AUTOSAR XML (schema 4.0)
standard types defined: float32, float64, sint16, sint32, sint8, uint16, uint32, uint8, void, boolean
package /ImplDataTypes
  7 x impl type, all with category=TYPE_REFERENCE, implementation-data-type=uint8, type-emitter=RTE:
    HeightImpType
    InclineImpType
    MultiStateBtnType
    SensorPositionType
    SensorWeightType
    SlideImpType
    StepMotorStepImpType
package /MappingSets
  data type mapping set MappingSet
package /PortInterfaces/ClientServer
  7 x client server interface:
    CsIf_HeightMotor
      operation Move
        arg Step: type=StepMotorStepImpType, direction=IN
    CsIf_HeightSensor
      operation GetPosition
        arg Arg_: type=SensorPositionType, direction=OUT
    CsIf_InclineMotor
      operation Move
        arg Step: type=StepMotorStepImpType, direction=IN
    CsIf_InclineSensor
      operation GetPosition
        arg Arg_: type=SensorPositionType, direction=OUT
    CsIf_SlideMotor
      operation Move
        arg Step: type=StepMotorStepImpType, direction=IN
    CsIf_SlideSensor
      operation GetPosition
        arg Arg_: type=SensorPositionType, direction=OUT
    CsIf_WeightSensor
      operation GetWeight
        arg Arg_: type=SensorWeightType, direction=OUT
package /PortInterfaces/SenderReceiver
  sender receiver interface SrIf_SeatCtrlBtns
    data HeightBtnState: type=MultiStateBtnType
    data InclineBtnState: type=MultiStateBtnType
    data SlideBtnState: type=MultiStateBtnType
  sender receiver interface SrIf_SeatCtrlData
    data Height: type=HeightImpType
    data Incline: type=InclineImpType
    data Slide: type=SlideImpType
package /SoftwareComponents
  application sw component type ECU
    provide port ppSeatCtrlData: provided-interface=SrIf_SeatCtrlData
    behavior Ibhv_ECU: data-type-mapping=MappingSet, handle-termination-and-restart=NO-SUPPORT
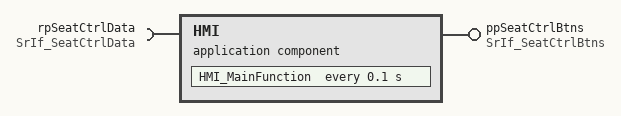
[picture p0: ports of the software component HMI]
  application sw component type HMI
    provide port ppSeatCtrlBtns: provided-interface=SrIf_SeatCtrlBtns
    require port rpSeatCtrlData: required-interface=SrIf_SeatCtrlData
    behavior Ibhv_HMI: data-type-mapping=MappingSet, handle-termination-and-restart=NO-SUPPORT
      timing event TE_HMI_MainFunction_100ms: start-on-event=HMI_MainFunction, period=0.1
      runnable HMI_MainFunction
        data-receive-point-by-arguments:
          access DRP_rpSeatCtrlData_Height: accessed-variable=rpSeatCtrlData.Height
          access DRP_rpSeatCtrlData_Incline: accessed-variable=rpSeatCtrlData.Incline
          access DRP_rpSeatCtrlData_Slide: accessed-variable=rpSeatCtrlData.Slide
        data-send-points:
          access DSP_ppSeatCtrlBtns_HeightBtnState: accessed-variable=ppSeatCtrlBtns.HeightBtnState
          access DSP_ppSeatCtrlBtns_InclineBtnState: accessed-variable=ppSeatCtrlBtns.InclineBtnState
          access DSP_ppSeatCtrlBtns_SlideBtnState: accessed-variable=ppSeatCtrlBtns.SlideBtnState
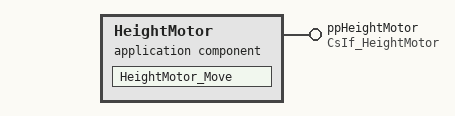
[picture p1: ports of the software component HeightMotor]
  application sw component type HeightMotor
    provide port ppHeightMotor: provided-interface=CsIf_HeightMotor
    behavior Ibhv_HeightMotor: data-type-mapping=MappingSet, handle-termination-and-restart=NO-SUPPORT
      operation invoked event OIE_ppHeightMotor_Move: start-on-event=HeightMotor_Move, operation=ppHeightMotor.Move
      runnable HeightMotor_Move
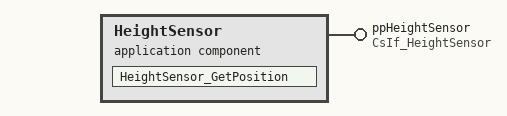
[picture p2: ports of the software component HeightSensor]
  application sw component type HeightSensor
    provide port ppHeightSensor: provided-interface=CsIf_HeightSensor
    behavior Ibhv_HeightSensor: data-type-mapping=MappingSet, handle-termination-and-restart=NO-SUPPORT
      operation invoked event OIE_ppHeightSensor_GetPosition: start-on-event=HeightSensor_GetPosition, operation=ppHeightSensor.GetPosition
      runnable HeightSensor_GetPosition
  10 x swc implementation, all with programming-language=C, sw-version=1.0.0, vendor-id=255:
    Impl_ECU: behavior=Ibhv_ECU
      code-descriptors:
        code Code: artifact-descriptors=autosar-engineering-object={short-label=SWC.c, category=SWSRC}
      resource consumption ResourceConsumption
    Impl_HMI: behavior=Ibhv_HMI
      code-descriptors:
        code Code: artifact-descriptors=autosar-engineering-object={short-label=SWC.c, category=SWSRC}
      resource consumption ResourceConsumption
    Impl_HeightMotor: behavior=Ibhv_HeightMotor
      code-descriptors:
        code Code: artifact-descriptors=autosar-engineering-object={short-label=SWC.c, category=SWSRC}
      resource consumption ResourceConsumption
    Impl_HeightSensor: behavior=Ibhv_HeightSensor
      code-descriptors:
        code Code: artifact-descriptors=autosar-engineering-object={short-label=SWC.c, category=SWSRC}
      resource consumption ResourceConsumption
    Impl_InclineMotor: behavior=Ibhv_InclineMotor
      code-descriptors:
        code Code: artifact-descriptors=autosar-engineering-object={short-label=SWC.c, category=SWSRC}
      resource consumption ResourceConsumption
    Impl_InclineSensor: behavior=Ibhv_InclineSensor
      code-descriptors:
        code Code: artifact-descriptors=autosar-engineering-object={short-label=SWC.c, category=SWSRC}
      resource consumption ResourceConsumption
    Impl_SeatMgr: behavior=Ibhv_SeatMgr
      code-descriptors:
        code Code: artifact-descriptors=autosar-engineering-object={short-label=SWC.c, category=SWSRC}
      resource consumption ResourceConsumption
    Impl_SlideMotor: behavior=Ibhv_SlideMotor
      code-descriptors:
        code Code: artifact-descriptors=autosar-engineering-object={short-label=SWC.c, category=SWSRC}
      resource consumption ResourceConsumption
    Impl_SlideSensor: behavior=Ibhv_SlideSensor
      code-descriptors:
        code Code: artifact-descriptors=autosar-engineering-object={short-label=SWC.c, category=SWSRC}
      resource consumption ResourceConsumption
    Impl_WeightSensor: behavior=Ibhv_WeightSensor
      code-descriptors:
        code Code: artifact-descriptors=autosar-engineering-object={short-label=SWC.c, category=SWSRC}
      resource consumption ResourceConsumption
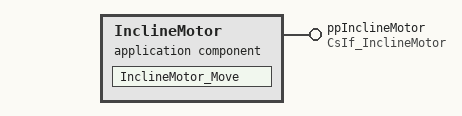
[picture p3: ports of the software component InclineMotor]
  application sw component type InclineMotor
    provide port ppInclineMotor: provided-interface=CsIf_InclineMotor
    behavior Ibhv_InclineMotor: data-type-mapping=MappingSet, handle-termination-and-restart=NO-SUPPORT
      operation invoked event OIE_ppInclineMotor_Move: start-on-event=InclineMotor_Move, operation=ppInclineMotor.Move
      runnable InclineMotor_Move
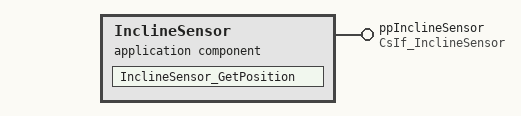
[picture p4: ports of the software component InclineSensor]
  application sw component type InclineSensor
    provide port ppInclineSensor: provided-interface=CsIf_InclineSensor
    behavior Ibhv_InclineSensor: data-type-mapping=MappingSet, handle-termination-and-restart=NO-SUPPORT
      operation invoked event OIE_ppInclineSensor_GetPosition: start-on-event=InclineSensor_GetPosition, operation=ppInclineSensor.GetPosition
      runnable InclineSensor_GetPosition
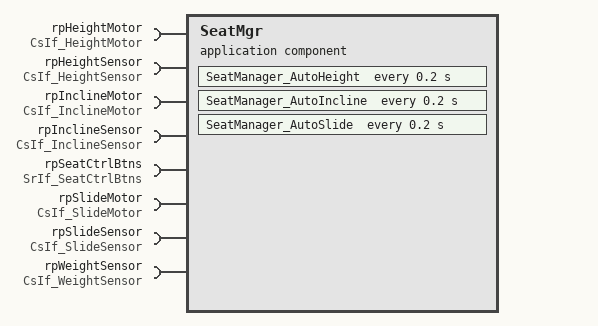
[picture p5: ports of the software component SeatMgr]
  application sw component type SeatMgr
    8 x require port:
      rpHeightMotor: required-interface=CsIf_HeightMotor
      rpHeightSensor: required-interface=CsIf_HeightSensor
      rpInclineMotor: required-interface=CsIf_InclineMotor
      rpInclineSensor: required-interface=CsIf_InclineSensor
      rpSeatCtrlBtns: required-interface=SrIf_SeatCtrlBtns
      rpSlideMotor: required-interface=CsIf_SlideMotor
      rpSlideSensor: required-interface=CsIf_SlideSensor
      rpWeightSensor: required-interface=CsIf_WeightSensor
    behavior Ibhv_SeatMgr: data-type-mapping=MappingSet, handle-termination-and-restart=NO-SUPPORT
      data received event DRE_rpSeatCtrlBtns_HeightBtnState: start-on-event=SeatManager_SetHeight, data=rpSeatCtrlBtns.HeightBtnState
      data received event DRE_rpSeatCtrlBtns_InclineBtnState: start-on-event=SeatManager_SetIncline, data=rpSeatCtrlBtns.InclineBtnState
      data received event DRE_rpSeatCtrlBtns_SlideBtnState: start-on-event=SeatManager_SetSlide, data=rpSeatCtrlBtns.SlideBtnState
      timing event TE_SeatManager_AutoHeight_200ms: start-on-event=SeatManager_AutoHeight, period=0.2
      timing event TE_SeatManager_AutoIncline_200ms: start-on-event=SeatManager_AutoIncline, period=0.2
      timing event TE_SeatManager_AutoSlide_200ms: start-on-event=SeatManager_AutoSlide, period=0.2
      6 x runnable:
        SeatManager_AutoHeight
          sync call SCP_rpHeightMotor_Move: operation=rpHeightMotor.Move, timeout=0.0
          sync call SCP_rpHeightSensor_GetPosition: operation=rpHeightSensor.GetPosition, timeout=0.0
        SeatManager_AutoIncline
          sync call SCP_rpInclineMotor_Move: operation=rpInclineMotor.Move, timeout=0.0
          sync call SCP_rpInclineSensor_GetPosition: operation=rpInclineSensor.GetPosition, timeout=0.0
        SeatManager_AutoSlide
          sync call SCP_rpSlideMotor_Move: operation=rpSlideMotor.Move, timeout=0.0
          sync call SCP_rpSlideSensor_GetPosition: operation=rpSlideSensor.GetPosition, timeout=0.0
        SeatManager_SetHeight
          data-receive-point-by-arguments:
            access DRP_rpSeatCtrlBtns_HeightBtnState: accessed-variable=rpSeatCtrlBtns.HeightBtnState
          sync call SCP_rpHeightMotor_Move: operation=rpHeightMotor.Move, timeout=0.0
        SeatManager_SetIncline
          data-receive-point-by-arguments:
            access DRP_rpSeatCtrlBtns_InclineBtnState: accessed-variable=rpSeatCtrlBtns.InclineBtnState
          sync call SCP_rpInclineMotor_Move: operation=rpInclineMotor.Move, timeout=0.0
        SeatManager_SetSlide
          data-receive-point-by-arguments:
            access DRP_rpSeatCtrlBtns_SlideBtnState: accessed-variable=rpSeatCtrlBtns.SlideBtnState
          sync call SCP_rpSlideMotor_Move: operation=rpSlideMotor.Move, timeout=0.0
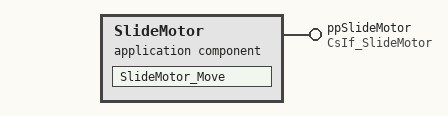
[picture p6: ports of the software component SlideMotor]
  application sw component type SlideMotor
    provide port ppSlideMotor: provided-interface=CsIf_SlideMotor
    behavior Ibhv_SlideMotor: data-type-mapping=MappingSet, handle-termination-and-restart=NO-SUPPORT
      operation invoked event OIE_ppSlideMotor_Move: start-on-event=SlideMotor_Move, operation=ppSlideMotor.Move
      runnable SlideMotor_Move
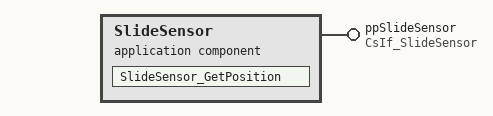
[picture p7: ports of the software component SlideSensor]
  application sw component type SlideSensor
    provide port ppSlideSensor: provided-interface=CsIf_SlideSensor
    behavior Ibhv_SlideSensor: data-type-mapping=MappingSet, handle-termination-and-restart=NO-SUPPORT
      operation invoked event OIE_ppSlideSensor_GetPosition: start-on-event=SlideSensor_GetPosition, operation=ppSlideSensor.GetPosition
      runnable SlideSensor_GetPosition
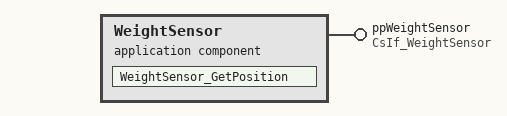
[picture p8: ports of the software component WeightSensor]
  application sw component type WeightSensor
    provide port ppWeightSensor: provided-interface=CsIf_WeightSensor
    behavior Ibhv_WeightSensor: data-type-mapping=MappingSet, handle-termination-and-restart=NO-SUPPORT
      operation invoked event OIE_ppWeightSensor_GetWeight: start-on-event=WeightSensor_GetPosition, operation=ppWeightSensor.GetWeight
      runnable WeightSensor_GetPosition
package /Compositions
  composition sw component type SR in SeatComposition
    10 x component:
      ECU: type=ECU
      HMI: type=HMI
      HeightMotor: type=HeightMotor
      HeightSensor: type=HeightSensor
      InclineMotor: type=InclineMotor
      InclineSensor: type=InclineSensor
      SeatMgr: type=SeatMgr
      SlideMotor: type=SlideMotor
      SlideSensor: type=SlideSensor
      WeightSensor: type=WeightSensor
    connect HMI.ppSeatCtrlBtns -> SeatMgr.rpSeatCtrlBtns
    connect HeightMotor.ppHeightMotor -> SeatMgr.rpHeightMotor
    connect HeightSensor.ppHeightSensor -> SeatMgr.rpHeightSensor
    connect InclineMotor.ppInclineMotor -> SeatMgr.rpInclineMotor
    connect InclineSensor.ppInclineSensor -> SeatMgr.rpInclineSensor
    connect SlideMotor.ppSlideMotor -> SeatMgr.rpSlideMotor
    connect SlideSensor.ppSlideSensor -> SeatMgr.rpSlideSensor
    connect WeightSensor.ppWeightSensor -> SeatMgr.rpWeightSensor
